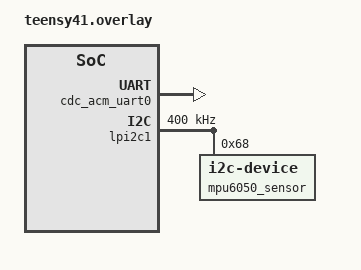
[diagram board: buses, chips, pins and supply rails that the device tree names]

&zephyr_udc0
{
	cdc_acm_uart0
	{
		compatible = "zephyr,cdc-acm-uart";
		label = "Zephyr USB CDC-ACM";
	};
};

/ {
    aliases
	{
        mpu6050test = &mpu6050_sensor;
    };
};

&lpi2c1
{
    status = "okay";
    clock-frequency = <I2C_BITRATE_FAST>;

    mpu6050_sensor: mpu6050@68
	{
        compatible = "i2c-device";
        reg = <0x68>;
    };
};
